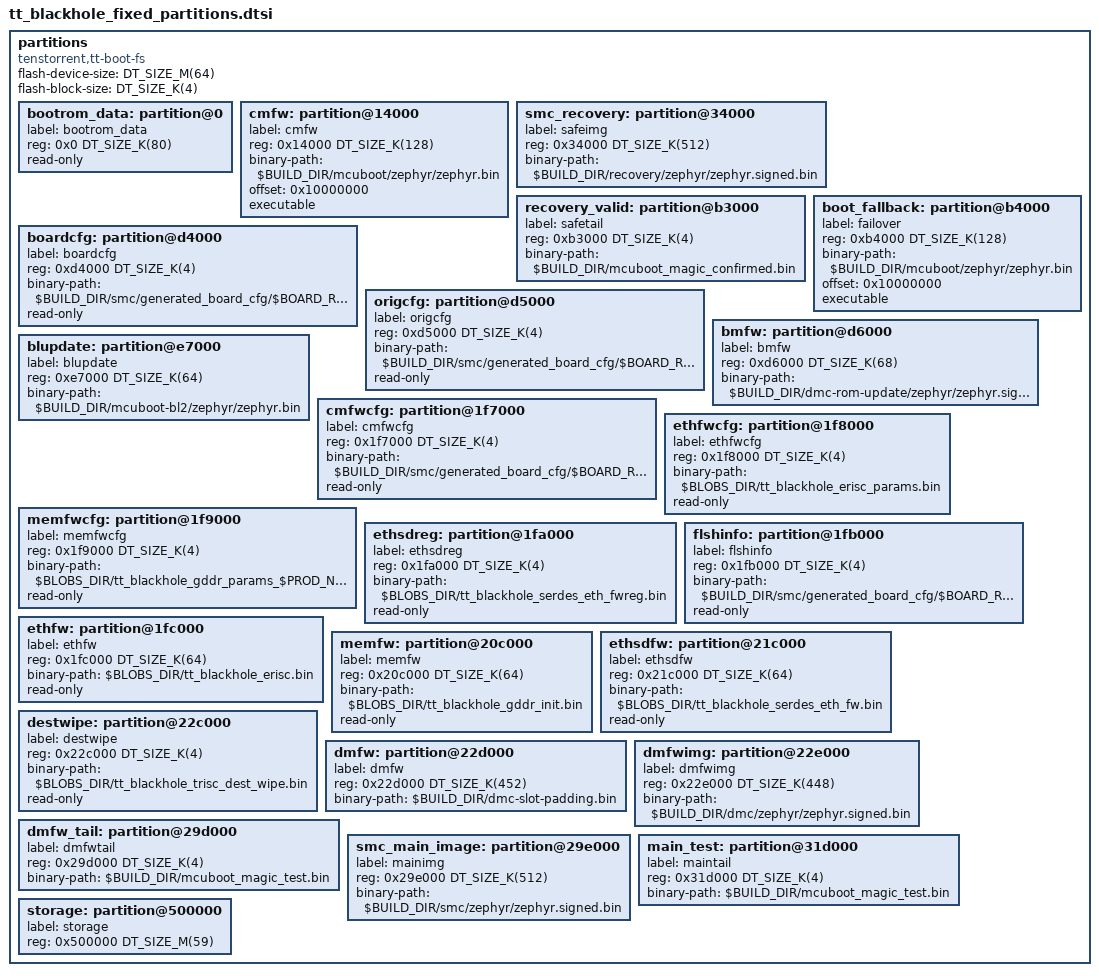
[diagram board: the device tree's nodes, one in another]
/*
 * Copyright (c) 2025 Tenstorrent AI ULC
 *
 * SPDX-License-Identifier: Apache-2.0
 */

#include <mem.h>

/* Fixed partitions for tt_blackhole board.
 *
 * These partition definitions will be included in both the SMC and DMC
 * devicetrees when the new fixed bootloader scheme is used.
 */

partitions {
	compatible = "tenstorrent,tt-boot-fs", "fixed-partitions";
	#address-cells = <1>;
	#size-cells = <1>;

	flash-device-size = <DT_SIZE_M(64)>;
	flash-block-size = <DT_SIZE_K(4)>;

	/*
	 * Just a placeholder for bootrom data.
	 * This region has tt-boot-fs descriptors.
	 */
	bootrom_data: partition@0 {
		label = "bootrom_data";
		reg = <0x0 DT_SIZE_K(80)>;
		read-only;
	};

	/*
	 * All partitions below here should eventually be mapped to binaries.
	 * These binaries will not change, and should provide a safe bootloader
	 * path in the event of an invalid main image.
	 */

	/*
	 * Install MCUBoot as the cmfw tag as well as the failover. Otherwise
	 * the bootrom may fail to load, as it expects a cmfw tag to be
	 * present.
	 */
	cmfw: partition@14000 {
		label = "cmfw";
		reg = <0x14000 DT_SIZE_K(128)>;
		binary-path = "$BUILD_DIR/mcuboot/zephyr/zephyr.bin";
		offset = <0x10000000>;
		executable;
	};

	/*
	 * This partition contains the recovery image. It will be
	 * loaded by MCUBoot if the primary image fails to validate.
	 * This binary is not used by the bootrom.
	 */
	smc_recovery: partition@34000 {
		label = "safeimg";
		reg = <0x34000 DT_SIZE_K(512)>;
		binary-path = "$BUILD_DIR/recovery/zephyr/zephyr.signed.bin";
	};

	/*
	 * This partition defines a binary blob that indicates the
	 * recovery image is valid and bootable to mcuboot.
	 */
	recovery_valid: partition@b3000 {
		label = "safetail";
		reg = <0xb3000 DT_SIZE_K(4)>;
		binary-path = "$BUILD_DIR/mcuboot_magic_confirmed.bin";
	};

	/*
	 * MCUBoot partition- will be loaded by bootrom.
	 * tagged as fail_over_image in tt-boot-fs,
	 * used if the primary image fails to validate.
	 */
	boot_fallback: partition@b4000 {
		label = "failover";
		reg = <0xb4000 DT_SIZE_K(128)>;
		binary-path = "$BUILD_DIR/mcuboot/zephyr/zephyr.bin";
		offset = <0x10000000>;
		executable;
	};

	boardcfg: partition@d4000 {
		label = "boardcfg";
		reg = <0xd4000 DT_SIZE_K(4)>;
		binary-path = "$BUILD_DIR/smc/generated_board_cfg/$BOARD_REV/read_only.bin";
		read-only;
	};

	origcfg: partition@d5000 {
		label = "origcfg";
		reg = <0xd5000 DT_SIZE_K(4)>;
		binary-path = "$BUILD_DIR/smc/generated_board_cfg/$BOARD_REV/fw_table.bin";
		read-only;
	};

	/* Partition for bootloader update image */
	bmfw: partition@d6000 {
		label = "bmfw";
		reg = <0xd6000 DT_SIZE_K(68)>;
		binary-path = "$BUILD_DIR/dmc-rom-update/zephyr/zephyr.signed.bin";
	};

	/* Partition for new MCUBoot image */
	blupdate: partition@e7000 {
		label = "blupdate";
		reg = <0xe7000 DT_SIZE_K(64)>;
		binary-path = "$BUILD_DIR/mcuboot-bl2/zephyr/zephyr.bin";
	};

	/* Leave a gap of 1 MB for future fixed partitions, if needed. */

	/* Partitions below here are expected to be updated in the field. */

	/* Firmware configuration blobs */
	cmfwcfg: partition@1f7000 {
		label = "cmfwcfg";
		reg = <0x1f7000 DT_SIZE_K(4)>;
		binary-path = "$BUILD_DIR/smc/generated_board_cfg/$BOARD_REV/fw_table.bin";
		read-only;
	};

	ethfwcfg: partition@1f8000 {
		label = "ethfwcfg";
		reg = <0x1f8000 DT_SIZE_K(4)>;
		binary-path = "$BLOBS_DIR/tt_blackhole_erisc_params.bin";
		read-only;
	};

	memfwcfg: partition@1f9000 {
		label = "memfwcfg";
		reg = <0x1f9000 DT_SIZE_K(4)>;
		binary-path = "$BLOBS_DIR/tt_blackhole_gddr_params_$PROD_NAME.bin";
		read-only;
	};

	ethsdreg: partition@1fa000 {
		label = "ethsdreg";
		reg = <0x1fa000 DT_SIZE_K(4)>;
		binary-path = "$BLOBS_DIR/tt_blackhole_serdes_eth_fwreg.bin";
		read-only;
	};

	flshinfo: partition@1fb000 {
		label = "flshinfo";
		reg = <0x1fb000 DT_SIZE_K(4)>;
		binary-path = "$BUILD_DIR/smc/generated_board_cfg/$BOARD_REV/flash_info.bin";
		read-only;
	};

	/* Remote chip firmware images */
	ethfw: partition@1fc000 {
		label = "ethfw";
		reg = <0x1fc000 DT_SIZE_K(64)>;
		binary-path = "$BLOBS_DIR/tt_blackhole_erisc.bin";
		read-only;
	};

	memfw: partition@20c000 {
		label = "memfw";
		reg = <0x20c000 DT_SIZE_K(64)>;
		binary-path = "$BLOBS_DIR/tt_blackhole_gddr_init.bin";
		read-only;
	};

	ethsdfw: partition@21c000 {
		label = "ethsdfw";
		reg = <0x21c000 DT_SIZE_K(64)>;
		binary-path = "$BLOBS_DIR/tt_blackhole_serdes_eth_fw.bin";
		read-only;
	};

	/* TRISC dest wipe firmware, loaded to Tensix L1 by wipe_dest() */
	destwipe: partition@22c000 {
		label = "destwipe";
		reg = <0x22c000 DT_SIZE_K(4)>;
		binary-path = "$BLOBS_DIR/tt_blackhole_trisc_dest_wipe.bin";
		read-only;
	};

	/* Update firmware image for the DMC, as seen by mcuboot */
	dmfw: partition@22d000 {
		label = "dmfw";
		reg = <0x22d000 DT_SIZE_K(452)>;
		binary-path = "$BUILD_DIR/dmc-slot-padding.bin";
	};

	/*
	 * Partition where image is actually written. Offset by 4KB to
	 * support swap using move.
	 */
	dmfwimg: partition@22e000 {
		label = "dmfwimg";
		reg = <0x22e000 DT_SIZE_K(448)>;
		binary-path = "$BUILD_DIR/dmc/zephyr/zephyr.signed.bin";
	};

	/*
	 * Image trailer for the DMC firmware update. Indicates to MCUBoot that
	 * the image is valid and should be booted in test mode.
	 */
	dmfw_tail: partition@29d000 {
		label = "dmfwtail";
		reg = <0x29d000 DT_SIZE_K(4)>;
		binary-path = "$BUILD_DIR/mcuboot_magic_test.bin";
	};

	/*
	 * This partition is used for the primary firmware image.
	 * it is loaded by MCUBoot. It is tagged as
	 * mainimg in tt-boot-fs, but isn't used by the bootrom.
	 */
	smc_main_image: partition@29e000 {
		label = "mainimg";
		reg = <0x29e000 DT_SIZE_K(512)>;
		binary-path = "$BUILD_DIR/smc/zephyr/zephyr.signed.bin";
	};

	/*
	 * This partition defines a binary blob that indicates the
	 * main image should be booted in test mode by mcuboot.
	 */
	main_test: partition@31d000 {
		label = "maintail";
		reg = <0x31d000 DT_SIZE_K(4)>;
		binary-path = "$BUILD_DIR/mcuboot_magic_test.bin";
	};

	/* Leave some space for future fixed partitions, if needed. */

	/* Free space for storage */
	storage: partition@500000 {
		label = "storage";
		reg = <0x500000 DT_SIZE_M(59)>;
	};
};
